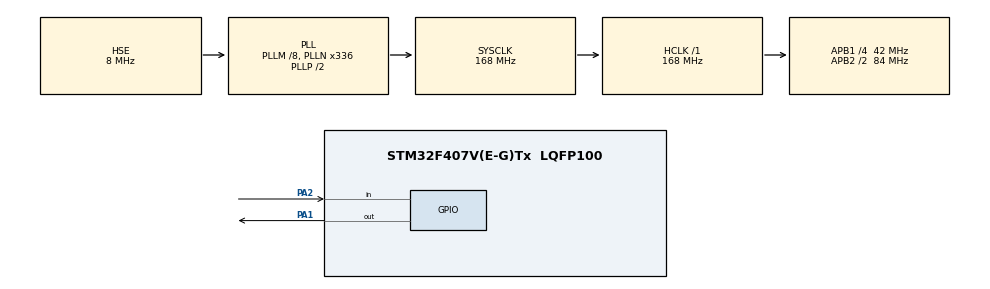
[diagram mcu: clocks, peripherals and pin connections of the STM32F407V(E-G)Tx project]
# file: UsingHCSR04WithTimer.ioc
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Mcu.Family=STM32F4
Mcu.Name=STM32F407V(E-G)Tx
Mcu.Package=LQFP100
NVIC.PriorityGroup=NVIC_PRIORITYGROUP_0
PA1.Signal=GPIO_Output
PA2.Signal=GPIO_Input
PH0-OSC_IN.Mode=HSE-External-Oscillator
PH0-OSC_IN.Signal=RCC_OSC_IN
PH1-OSC_OUT.Mode=HSE-External-Oscillator
PH1-OSC_OUT.Signal=RCC_OSC_OUT
ProjectManager.HeapSize=0x200
ProjectManager.StackSize=0x400
ProjectManager.TargetToolchain=STM32CubeIDE
RCC.48MHZClocksFreq_Value=48000000
RCC.AHBFreq_Value=168000000
RCC.APB1CLKDivider=RCC_HCLK_DIV4
RCC.APB1Freq_Value=42000000
RCC.APB1TimFreq_Value=84000000
RCC.APB2CLKDivider=RCC_HCLK_DIV2
RCC.APB2Freq_Value=84000000
RCC.APB2TimFreq_Value=168000000
RCC.CortexFreq_Value=168000000
RCC.HCLKFreq_Value=168000000
RCC.HSE_VALUE=8000000
RCC.HSI_VALUE=16000000
RCC.PLLM=8
RCC.PLLN=336
RCC.PLLQ=7
RCC.PLLSourceVirtual=RCC_PLLSOURCE_HSE
RCC.SYSCLKFreq_VALUE=168000000
RCC.SYSCLKSource=RCC_SYSCLKSOURCE_PLLCLK
RCC.VCOOutputFreq_Value=336000000
TIM2.AutoReloadPreload=TIM_AUTORELOAD_PRELOAD_ENABLE
TIM2.Period=4294967294
TIM2.Prescaler=84-1
TIM6.AutoReloadPreload=TIM_AUTORELOAD_PRELOAD_ENABLE
TIM6.Prescaler=84-1
VP_TIM2_VS_ClockSourceINT.Mode=Internal
VP_TIM6_VS_ClockSourceINT.Mode=Enable_Timer
board=STM32F407G-DISC1

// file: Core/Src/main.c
/* USER CODE BEGIN Header */
/**
  ******************************************************************************
  * @file           : main.c
  * @brief          : Main program body
  ******************************************************************************
  * @attention
  *
  * Copyright (c) 2024 STMicroelectronics.
  * All rights reserved.
  *
  * This software is licensed under terms that can be found in the LICENSE file
  * in the root directory of this software component.
  * If no LICENSE file comes with this software, it is provided AS-IS.
  *
  ******************************************************************************
  */
/* USER CODE END Header */
#include "main.h"

TIM_HandleTypeDef htim2;
TIM_HandleTypeDef htim6;

/* USER CODE BEGIN PV */
int abc =0;
uint32_t duration = 0;
uint32_t start_time = 0;
uint32_t end_time = 0;
uint32_t timeOut = 0;
float distance;

/* USER CODE END PV */

void SystemClock_Config(void);
static void MX_GPIO_Init(void);
static void MX_TIM6_Init(void);
static void MX_TIM2_Init(void);

/* USER CODE BEGIN 0 */
void delay(uint16_t time){
	__HAL_TIM_SET_COUNTER(&htim6, 0);
	while(__HAL_TIM_GET_COUNTER(&htim6) < time);
}

uint32_t  GetMicrosecond(void){
	return __HAL_TIM_GET_COUNTER(&htim2);
}

/* USER CODE END 0 */

int main(void)
{

  /* MCU Configuration--------------------------------------------------------*/

  /* Reset of all peripherals, Initializes the Flash interface and the Systick. */
  HAL_Init();

  /* Configure the system clock */
  SystemClock_Config();

  /* Initialize all configured peripherals */
  MX_GPIO_Init();
  MX_TIM6_Init();
  MX_TIM2_Init();
  /* USER CODE BEGIN 2 */
  HAL_TIM_Base_Start(&htim6);
  HAL_TIM_Base_Start(&htim2);
  /* USER CODE END 2 */

  /* Infinite loop */
  while (1)
  {

    /* USER CODE BEGIN 3 */
	  HAL_GPIO_WritePin(GPIOA, GPIO_PIN_1, 1);// Trig pini HIGH (PA1)
	  delay(10);            // 10 µs bekle
	  HAL_GPIO_WritePin(GPIOA, GPIO_PIN_1, 0);
	  abc+=15;

	  timeOut = GetMicrosecond();
	  while(HAL_GPIO_ReadPin(GPIOA, GPIO_PIN_2) == GPIO_PIN_RESET){
		  if((GetMicrosecond()-timeOut) > 30000){
			  break;
		  }
	  }
	  start_time = GetMicrosecond();
	  timeOut = GetMicrosecond();
	  while(HAL_GPIO_ReadPin(GPIOA, GPIO_PIN_2) == GPIO_PIN_SET){
		  if((GetMicrosecond()-timeOut) > 30000){
			  break;
		  }
	  }
	  end_time = GetMicrosecond();

	  duration = end_time - start_time;
	  distance = (duration * 0.0343)/2;
  }
  /* USER CODE END 3 */
}

void SystemClock_Config(void)
{
  RCC_OscInitTypeDef RCC_OscInitStruct = {0};
  RCC_ClkInitTypeDef RCC_ClkInitStruct = {0};

  /** Configure the main internal regulator output voltage
  */
  __HAL_RCC_PWR_CLK_ENABLE();
  __HAL_PWR_VOLTAGESCALING_CONFIG(PWR_REGULATOR_VOLTAGE_SCALE1);

  /** Initializes the RCC Oscillators according to the specified parameters
  * in the RCC_OscInitTypeDef structure.
  */
  RCC_OscInitStruct.OscillatorType = RCC_OSCILLATORTYPE_HSE;
  RCC_OscInitStruct.HSEState = RCC_HSE_ON;
  RCC_OscInitStruct.PLL.PLLState = RCC_PLL_ON;
  RCC_OscInitStruct.PLL.PLLSource = RCC_PLLSOURCE_HSE;
  RCC_OscInitStruct.PLL.PLLM = 8;
  RCC_OscInitStruct.PLL.PLLN = 336;
  RCC_OscInitStruct.PLL.PLLP = RCC_PLLP_DIV2;
  RCC_OscInitStruct.PLL.PLLQ = 7;
  if (HAL_RCC_OscConfig(&RCC_OscInitStruct) != HAL_OK)
  {
    Error_Handler();
  }

  /** Initializes the CPU, AHB and APB buses clocks
  */
  RCC_ClkInitStruct.ClockType = RCC_CLOCKTYPE_HCLK|RCC_CLOCKTYPE_SYSCLK
                              |RCC_CLOCKTYPE_PCLK1|RCC_CLOCKTYPE_PCLK2;
  RCC_ClkInitStruct.SYSCLKSource = RCC_SYSCLKSOURCE_PLLCLK;
  RCC_ClkInitStruct.AHBCLKDivider = RCC_SYSCLK_DIV1;
  RCC_ClkInitStruct.APB1CLKDivider = RCC_HCLK_DIV4;
  RCC_ClkInitStruct.APB2CLKDivider = RCC_HCLK_DIV2;

  if (HAL_RCC_ClockConfig(&RCC_ClkInitStruct, FLASH_LATENCY_5) != HAL_OK)
  {
    Error_Handler();
  }
}

static void MX_TIM2_Init(void)
{

  TIM_ClockConfigTypeDef sClockSourceConfig = {0};
  TIM_MasterConfigTypeDef sMasterConfig = {0};

  htim2.Instance = TIM2;
  htim2.Init.Prescaler = 84-1;
  htim2.Init.CounterMode = TIM_COUNTERMODE_UP;
  htim2.Init.Period = 4294967294;
  htim2.Init.ClockDivision = TIM_CLOCKDIVISION_DIV1;
  htim2.Init.AutoReloadPreload = TIM_AUTORELOAD_PRELOAD_ENABLE;
  if (HAL_TIM_Base_Init(&htim2) != HAL_OK)
  {
    Error_Handler();
  }
  sClockSourceConfig.ClockSource = TIM_CLOCKSOURCE_INTERNAL;
  if (HAL_TIM_ConfigClockSource(&htim2, &sClockSourceConfig) != HAL_OK)
  {
    Error_Handler();
  }
  sMasterConfig.MasterOutputTrigger = TIM_TRGO_RESET;
  sMasterConfig.MasterSlaveMode = TIM_MASTERSLAVEMODE_DISABLE;
  if (HAL_TIMEx_MasterConfigSynchronization(&htim2, &sMasterConfig) != HAL_OK)
  {
    Error_Handler();
  }

}

static void MX_TIM6_Init(void)
{

  TIM_MasterConfigTypeDef sMasterConfig = {0};

  htim6.Instance = TIM6;
  htim6.Init.Prescaler = 84-1;
  htim6.Init.CounterMode = TIM_COUNTERMODE_UP;
  htim6.Init.Period = 65535;
  htim6.Init.AutoReloadPreload = TIM_AUTORELOAD_PRELOAD_ENABLE;
  if (HAL_TIM_Base_Init(&htim6) != HAL_OK)
  {
    Error_Handler();
  }
  sMasterConfig.MasterOutputTrigger = TIM_TRGO_RESET;
  sMasterConfig.MasterSlaveMode = TIM_MASTERSLAVEMODE_DISABLE;
  if (HAL_TIMEx_MasterConfigSynchronization(&htim6, &sMasterConfig) != HAL_OK)
  {
    Error_Handler();
  }

}

static void MX_GPIO_Init(void)
{
  GPIO_InitTypeDef GPIO_InitStruct = {0};

  /* GPIO Ports Clock Enable */
  __HAL_RCC_GPIOH_CLK_ENABLE();
  __HAL_RCC_GPIOA_CLK_ENABLE();

  /*Configure GPIO pin Output Level */
  HAL_GPIO_WritePin(GPIOA, GPIO_PIN_1, GPIO_PIN_RESET);

  /*Configure GPIO pin : PA1 */
  GPIO_InitStruct.Pin = GPIO_PIN_1;
  GPIO_InitStruct.Mode = GPIO_MODE_OUTPUT_PP;
  GPIO_InitStruct.Pull = GPIO_NOPULL;
  GPIO_InitStruct.Speed = GPIO_SPEED_FREQ_LOW;
  HAL_GPIO_Init(GPIOA, &GPIO_InitStruct);

  /*Configure GPIO pin : PA2 */
  GPIO_InitStruct.Pin = GPIO_PIN_2;
  GPIO_InitStruct.Mode = GPIO_MODE_INPUT;
  GPIO_InitStruct.Pull = GPIO_NOPULL;
  HAL_GPIO_Init(GPIOA, &GPIO_InitStruct);

}

void Error_Handler(void)
{
  __disable_irq();
  while (1)
  {
  }
}
